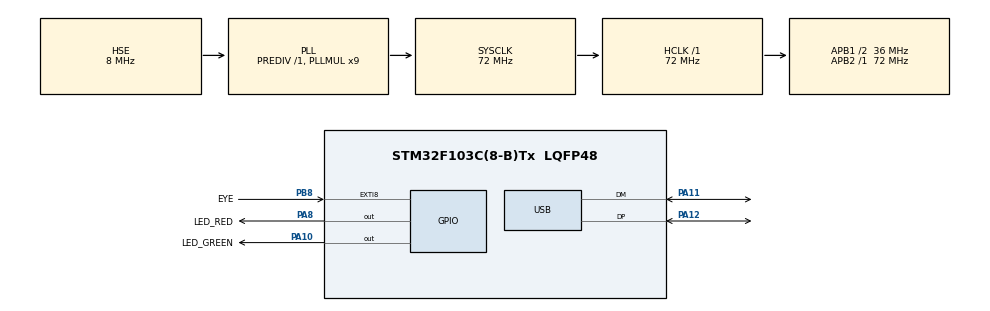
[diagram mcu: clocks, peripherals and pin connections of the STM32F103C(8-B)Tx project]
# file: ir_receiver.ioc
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Mcu.Family=STM32F1
Mcu.Name=STM32F103C(8-B)Tx
Mcu.Package=LQFP48
NVIC.EXTI9_5_IRQn=true\:0\:0\:false\:false\:true\:true\:true\:true
NVIC.PriorityGroup=NVIC_PRIORITYGROUP_4
NVIC.TIM2_IRQn=true\:1\:0\:true\:false\:true\:true\:true\:true
NVIC.USB_LP_CAN1_RX0_IRQn=true\:1\:0\:true\:false\:true\:false\:true\:true
PA10.GPIO_Label=LED_GREEN
PA10.GPIO_PuPd=GPIO_PULLUP
PA10.PinState=GPIO_PIN_SET
PA10.Signal=GPIO_Output
PA11.Mode=Device
PA11.Signal=USB_DM
PA12.Mode=Device
PA12.Signal=USB_DP
PA13.Mode=Trace_Asynchronous_SW
PA13.Signal=SYS_JTMS-SWDIO
PA14.Mode=Trace_Asynchronous_SW
PA14.Signal=SYS_JTCK-SWCLK
PA8.GPIO_Label=LED_RED
PA8.GPIO_PuPd=GPIO_PULLUP
PA8.PinState=GPIO_PIN_SET
PA8.Signal=GPIO_Output
PB3.Mode=Trace_Asynchronous_SW
PB3.Signal=SYS_JTDO-TRACESWO
PB8.GPIO_Label=EYE
PB8.GPIO_ModeDefaultEXTI=GPIO_MODE_IT_RISING_FALLING
PB8.GPIO_PuPd=GPIO_PULLUP
PB8.Signal=GPXTI8
PD0-OSC_IN.Mode=HSE-External-Oscillator
PD0-OSC_IN.Signal=RCC_OSC_IN
PD1-OSC_OUT.Mode=HSE-External-Oscillator
PD1-OSC_OUT.Signal=RCC_OSC_OUT
ProjectManager.HeapSize=0x200
ProjectManager.StackSize=0x400
ProjectManager.TargetToolchain=STM32CubeIDE
RCC.AHBFreq_Value=72000000
RCC.APB1CLKDivider=RCC_HCLK_DIV2
RCC.APB1Freq_Value=36000000
RCC.APB1TimFreq_Value=72000000
RCC.APB2Freq_Value=72000000
RCC.APB2TimFreq_Value=72000000
RCC.HCLKFreq_Value=72000000
RCC.PLLMUL=RCC_PLL_MUL9
RCC.SYSCLKFreq_VALUE=72000000
RCC.SYSCLKSource=RCC_SYSCLKSOURCE_PLLCLK
RCC.USBFreq_Value=48000000
RCC.USBPrescaler=RCC_USBCLKSOURCE_PLL_DIV1_5
TIM2.Period=19999
TIM2.Prescaler=71
TIM3.Period=19999
TIM3.Prescaler=35
USB_DEVICE.CLASS_NAME_FS=CDC
USB_DEVICE.MANUFACTURER_STRING=Skrrmrchoh
USB_DEVICE.PRODUCT_STRING_CDC_FS=IR Receiver
USB_DEVICE.VirtualMode=Cdc
USB_DEVICE.VirtualModeFS=Cdc_FS
VP_TIM2_VS_ClockSourceINT.Mode=Internal
VP_TIM3_VS_ClockSourceINT.Mode=Internal
VP_USB_DEVICE_VS_USB_DEVICE_CDC_FS.Mode=CDC_FS
board=custom

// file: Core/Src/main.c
/* USER CODE BEGIN Header */
/**
  ******************************************************************************
  * @file           : main.c
  * @brief          : Main program body
  ******************************************************************************
  * @attention
  *
  * Copyright (c) 2022 STMicroelectronics.
  * All rights reserved.
  *
  * This software is licensed under terms that can be found in the LICENSE file
  * in the root directory of this software component.
  * If no LICENSE file comes with this software, it is provided AS-IS.
  *
  ******************************************************************************
  */
/* USER CODE END Header */
#include "main.h"
#include "usb_device.h"

/* USER CODE BEGIN Includes */
#include "usbd_cdc_if.h"
/* USER CODE END Includes */

 TIM_HandleTypeDef htim3;

void SystemClock_Config(void);
static void MX_GPIO_Init(void);
static void MX_TIM2_Init(void);
static void MX_TIM3_Init(void);

int main(void)
{

  /* MCU Configuration--------------------------------------------------------*/

  /* Reset of all peripherals, Initializes the Flash interface and the Systick. */
  HAL_Init();

  /* Configure the system clock */
  SystemClock_Config();

  /* Initialize all configured peripherals */
  MX_GPIO_Init();
  MX_USB_DEVICE_Init();
  MX_TIM2_Init();
  MX_TIM3_Init();

  /* Infinite loop */
  while (1)
  {

    /* USER CODE BEGIN 3 */

	  HAL_Delay(500);

	  /*HAL_GPIO_WritePin(GPIOA, GPIO_PIN_8, GPIO_PIN_RESET);
	  //CDC_Transmit_FS("123\r\n", 5);
	  HAL_Delay(500);
	  HAL_GPIO_WritePin(GPIOA, GPIO_PIN_8, GPIO_PIN_SET);
	  //CDC_Transmit_FS("456\r\n", 5);
	  HAL_Delay(500);*/
  }
  /* USER CODE END 3 */
}

void SystemClock_Config(void)
{
  RCC_OscInitTypeDef RCC_OscInitStruct = {0};
  RCC_ClkInitTypeDef RCC_ClkInitStruct = {0};
  RCC_PeriphCLKInitTypeDef PeriphClkInit = {0};

  /** Initializes the RCC Oscillators according to the specified parameters
  * in the RCC_OscInitTypeDef structure.
  */
  RCC_OscInitStruct.OscillatorType = RCC_OSCILLATORTYPE_HSE;
  RCC_OscInitStruct.HSEState = RCC_HSE_ON;
  RCC_OscInitStruct.HSEPredivValue = RCC_HSE_PREDIV_DIV1;
  RCC_OscInitStruct.HSIState = RCC_HSI_ON;
  RCC_OscInitStruct.PLL.PLLState = RCC_PLL_ON;
  RCC_OscInitStruct.PLL.PLLSource = RCC_PLLSOURCE_HSE;
  RCC_OscInitStruct.PLL.PLLMUL = RCC_PLL_MUL9;
  if (HAL_RCC_OscConfig(&RCC_OscInitStruct) != HAL_OK)
  {
    Error_Handler();
  }

  /** Initializes the CPU, AHB and APB buses clocks
  */
  RCC_ClkInitStruct.ClockType = RCC_CLOCKTYPE_HCLK|RCC_CLOCKTYPE_SYSCLK
                              |RCC_CLOCKTYPE_PCLK1|RCC_CLOCKTYPE_PCLK2;
  RCC_ClkInitStruct.SYSCLKSource = RCC_SYSCLKSOURCE_PLLCLK;
  RCC_ClkInitStruct.AHBCLKDivider = RCC_SYSCLK_DIV1;
  RCC_ClkInitStruct.APB1CLKDivider = RCC_HCLK_DIV2;
  RCC_ClkInitStruct.APB2CLKDivider = RCC_HCLK_DIV1;

  if (HAL_RCC_ClockConfig(&RCC_ClkInitStruct, FLASH_LATENCY_2) != HAL_OK)
  {
    Error_Handler();
  }
  PeriphClkInit.PeriphClockSelection = RCC_PERIPHCLK_USB;
  PeriphClkInit.UsbClockSelection = RCC_USBCLKSOURCE_PLL_DIV1_5;
  if (HAL_RCCEx_PeriphCLKConfig(&PeriphClkInit) != HAL_OK)
  {
    Error_Handler();
  }
}

static void MX_TIM2_Init(void)
{

  LL_TIM_InitTypeDef TIM_InitStruct = {0};

  /* Peripheral clock enable */
  LL_APB1_GRP1_EnableClock(LL_APB1_GRP1_PERIPH_TIM2);

  /* TIM2 interrupt Init */
  NVIC_SetPriority(TIM2_IRQn, NVIC_EncodePriority(NVIC_GetPriorityGrouping(),1, 0));
  NVIC_EnableIRQ(TIM2_IRQn);

  TIM_InitStruct.Prescaler = 71;
  TIM_InitStruct.CounterMode = LL_TIM_COUNTERMODE_UP;
  TIM_InitStruct.Autoreload = 19999;
  TIM_InitStruct.ClockDivision = LL_TIM_CLOCKDIVISION_DIV1;
  LL_TIM_Init(TIM2, &TIM_InitStruct);
  LL_TIM_DisableARRPreload(TIM2);
  LL_TIM_SetClockSource(TIM2, LL_TIM_CLOCKSOURCE_INTERNAL);
  LL_TIM_SetTriggerOutput(TIM2, LL_TIM_TRGO_RESET);
  LL_TIM_DisableMasterSlaveMode(TIM2);

}

static void MX_TIM3_Init(void)
{

  TIM_ClockConfigTypeDef sClockSourceConfig = {0};
  TIM_MasterConfigTypeDef sMasterConfig = {0};

  htim3.Instance = TIM3;
  htim3.Init.Prescaler = 35;
  htim3.Init.CounterMode = TIM_COUNTERMODE_UP;
  htim3.Init.Period = 19999;
  htim3.Init.ClockDivision = TIM_CLOCKDIVISION_DIV1;
  htim3.Init.AutoReloadPreload = TIM_AUTORELOAD_PRELOAD_DISABLE;
  if (HAL_TIM_Base_Init(&htim3) != HAL_OK)
  {
    Error_Handler();
  }
  sClockSourceConfig.ClockSource = TIM_CLOCKSOURCE_INTERNAL;
  if (HAL_TIM_ConfigClockSource(&htim3, &sClockSourceConfig) != HAL_OK)
  {
    Error_Handler();
  }
  sMasterConfig.MasterOutputTrigger = TIM_TRGO_RESET;
  sMasterConfig.MasterSlaveMode = TIM_MASTERSLAVEMODE_DISABLE;
  if (HAL_TIMEx_MasterConfigSynchronization(&htim3, &sMasterConfig) != HAL_OK)
  {
    Error_Handler();
  }

}

static void MX_GPIO_Init(void)
{
  LL_EXTI_InitTypeDef EXTI_InitStruct = {0};
  LL_GPIO_InitTypeDef GPIO_InitStruct = {0};

  /* GPIO Ports Clock Enable */
  LL_APB2_GRP1_EnableClock(LL_APB2_GRP1_PERIPH_GPIOD);
  LL_APB2_GRP1_EnableClock(LL_APB2_GRP1_PERIPH_GPIOA);
  LL_APB2_GRP1_EnableClock(LL_APB2_GRP1_PERIPH_GPIOB);

  /**/
  LL_GPIO_SetOutputPin(GPIOA, LED_RED_Pin|LED_GREEN_Pin);

  /**/
  GPIO_InitStruct.Pin = LED_RED_Pin|LED_GREEN_Pin;
  GPIO_InitStruct.Mode = LL_GPIO_MODE_OUTPUT;
  GPIO_InitStruct.Speed = LL_GPIO_SPEED_FREQ_LOW;
  GPIO_InitStruct.OutputType = LL_GPIO_OUTPUT_PUSHPULL;
  GPIO_InitStruct.Pull = LL_GPIO_PULL_UP;
  LL_GPIO_Init(GPIOA, &GPIO_InitStruct);

  /**/
  LL_GPIO_AF_SetEXTISource(LL_GPIO_AF_EXTI_PORTB, LL_GPIO_AF_EXTI_LINE8);

  /**/
  EXTI_InitStruct.Line_0_31 = LL_EXTI_LINE_8;
  EXTI_InitStruct.LineCommand = ENABLE;
  EXTI_InitStruct.Mode = LL_EXTI_MODE_IT;
  EXTI_InitStruct.Trigger = LL_EXTI_TRIGGER_RISING_FALLING;
  LL_EXTI_Init(&EXTI_InitStruct);

  /**/
  LL_GPIO_SetPinPull(EYE_GPIO_Port, EYE_Pin, LL_GPIO_PULL_UP);

  /**/
  LL_GPIO_SetPinMode(EYE_GPIO_Port, EYE_Pin, LL_GPIO_MODE_INPUT);

  /* EXTI interrupt init*/
  NVIC_SetPriority(EXTI9_5_IRQn, NVIC_EncodePriority(NVIC_GetPriorityGrouping(),0, 0));
  NVIC_EnableIRQ(EXTI9_5_IRQn);

}

void Error_Handler(void)
{
  __disable_irq();
  while (1)
  {
  }
}
